# MCXN947_cm33_core0 register map
Vendor: nxp.com; File version: 1.0
CPU: CM33 r2p0, little endian, MPU, FPU, VTOR, 3 interrupt priority bits
Registers are 32-bit, read-write, reset 0x0 unless marked. A register's access mark holds for its fields unless they carry their own. Offsets are from the block's base; [hi:lo] are bit positions; {n}, {i} and the like mark numbered series; 'fields as' and 'values as' point back to an identical list.

## PORT0 — PORT
Base 0x40116000
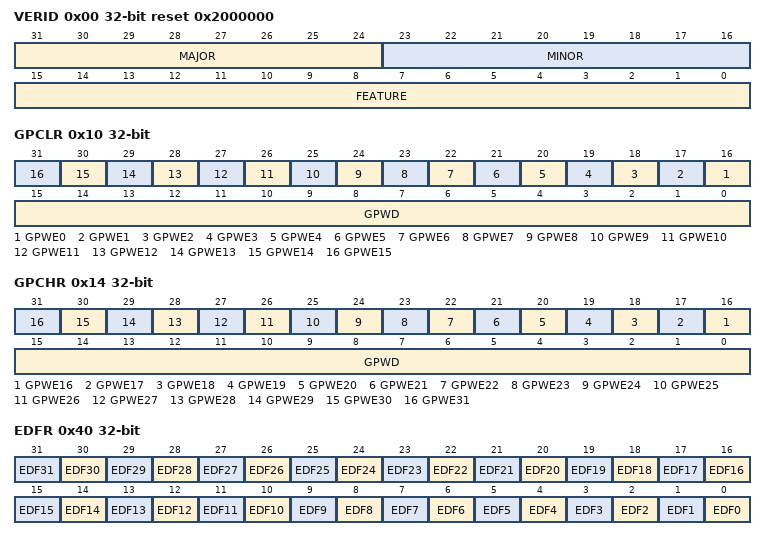
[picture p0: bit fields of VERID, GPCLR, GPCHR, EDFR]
0x00 VERID ro reset 0x2000000 — Version ID
  [31:24] MAJOR — Major Version Number
  [23:16] MINOR — Minor Version Number
  [15:0] FEATURE — Feature Specification Number
    0=Basic implementation
0x10 GPCLR — Global Pin Control Low
  [n+16] GPWE{n} (n=0..15) — Global Pin Write Enable
    0=gpwe0 (Not updated); 1=gpwe1 (Updated)
  [15:0] GPWD — Global Pin Write Data
0x14 GPCHR — Global Pin Control High
  [n] GPWE{n} (n=16..31) — Global Pin Write Enable
    0=gpwe0 (Not updated); 1=gpwe1 (Updated)
  [15:0] GPWD — Global Pin Write Data
0x20 CONFIG — Configuration
  [0] RANGE — Port Voltage Range
    0=1.71 V-3.6 V; 1=2.70 V-3.6 V
0x40 EDFR ro reset not defined — EFT Detect Flag
  [all] fields
    0=edie0 (No EFT event detected); 1=edie1 (High or/and low EFT event detected)
  [n] EDF{n} (n=0..31) — EFT Detect Flag
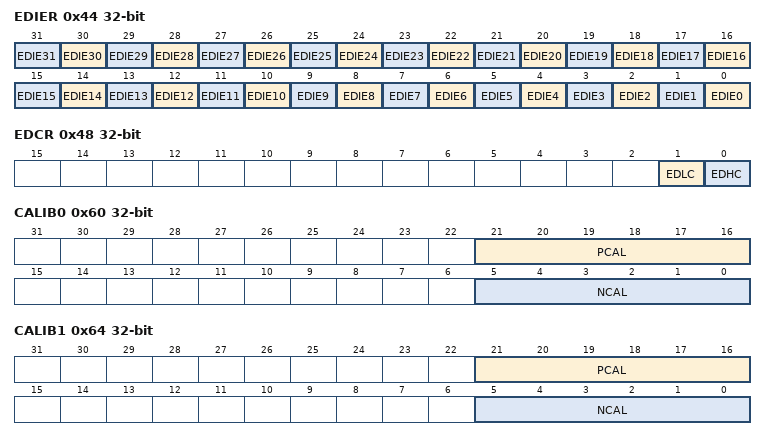
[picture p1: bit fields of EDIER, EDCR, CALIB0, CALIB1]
0x44 EDIER — EFT Detect Interrupt Enable
  [all] fields
    0=edie0 (Interrupt not generated upon detection of the EFT event); 1=edie1 (Interrupt generated upon detection of the EFT event)
  [n] EDIE{n} (n=0..31) — EFT Detect Interrupt Enable
0x48 EDCR — EFT Detect Clear
  [1] EDLC — EFT Detect Low Clear
    0=Does not clear; 1=Clears
  [0] EDHC — EFT Detect High Clear
    0=Does not clear; 1=Clears
0x60 CALIB0 (reset mask 0xFFC0FFC0) — Calibration 0
  [21:16] PCAL — Calibration of PMOS Output Driver
  [5:0] NCAL — Calibration of NMOS Output Driver
0x64 CALIB1 (reset mask 0xFFC0FFC0) — Calibration 1
  fields as CALIB0
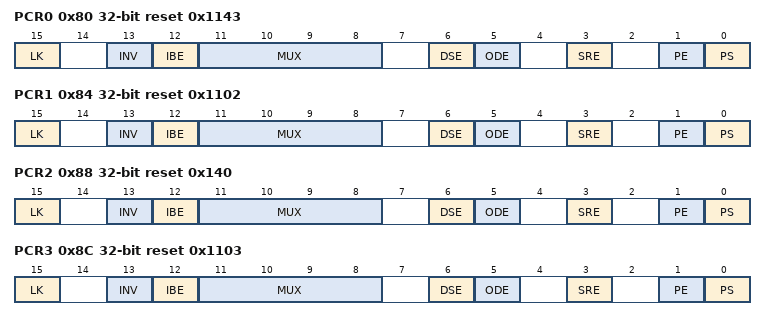
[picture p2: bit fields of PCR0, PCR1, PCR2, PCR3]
0x80 PCR0 reset 0x1143 — Pin Control 0
  [15] LK — Lock Register
    0=Does not lock; 1=Locks
  [13] INV — Invert Input
    0=Does not invert; 1=Inverts
  [12] IBE — Input Buffer Enable
    0=Disables; 1=Enables
  [11:8] MUX — Pin Multiplex Control
    0=Alternative 0 (GPIO); {v}=Alternative {v} (chip-specific) (v=1..13)
  [6] DSE — Drive Strength Enable
    0=Low; 1=High
  [5] ODE — Open Drain Enable
    0=Disables; 1=Enables
  [3] SRE — Slew Rate Enable
    0=Fast; 1=Slow
  [1] PE — Pull Enable
    0=Disables; 1=Enables
  [0] PS — Pull Select
    0=Enables internal pulldown resistor; 1=Enables internal pullup resistor
0x84 PCR1 reset 0x1102 — Pin Control 1
  fields as PCR0
0x88 PCR2 reset 0x140 — Pin Control 2
  fields as PCR0
0x8C PCR3 reset 0x1103 — Pin Control 3
  fields as PCR0
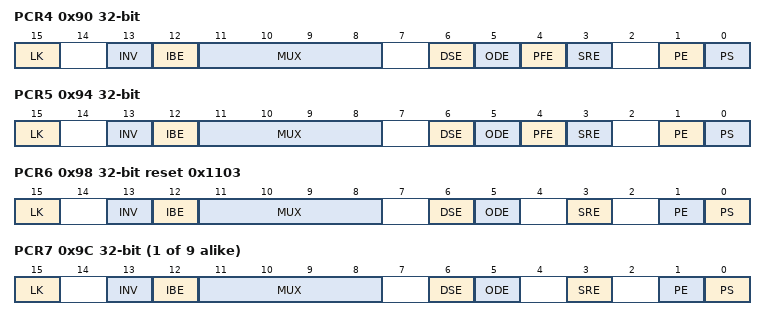
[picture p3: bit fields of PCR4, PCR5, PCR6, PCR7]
0x90 PCR4 — Pin Control 4
  [15] LK — Lock Register
    0=Does not lock; 1=Locks
  [13] INV — Invert Input
    0=Does not invert; 1=Inverts
  [12] IBE — Input Buffer Enable
    0=Disables; 1=Enables
  [11:8] MUX — Pin Multiplex Control
    values as PCR0.MUX
  [6] DSE — Drive Strength Enable
    0=Low; 1=High
  [5] ODE — Open Drain Enable
    0=Disables; 1=Enables
  [4] PFE — Passive Filter Enable
    0=Disables; 1=Enables
  [3] SRE — Slew Rate Enable
    0=Fast; 1=Slow
  [1] PE — Pull Enable
    0=Disables; 1=Enables
  [0] PS — Pull Select
    values as PCR0.PS
0x94 PCR5 — Pin Control 5
  fields as PCR4
0x98 PCR6 reset 0x1103 — Pin Control 6
  fields as PCR0
{0x80+4i} PCR{i} (i=7..15) — Pin Control {i}
  fields as PCR0
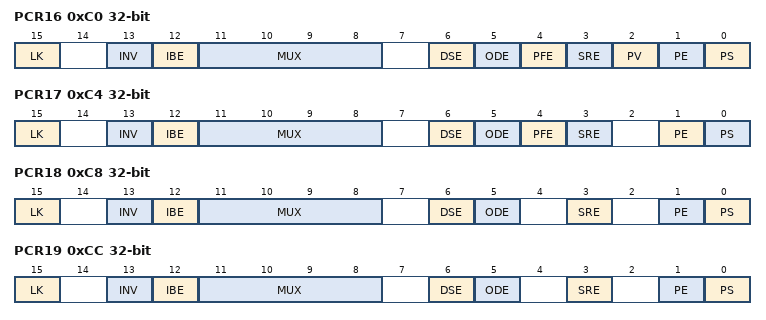
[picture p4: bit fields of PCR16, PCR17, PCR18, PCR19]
0xC0 PCR16 — Pin Control 16
  [15] LK — Lock Register
    0=Does not lock; 1=Locks
  [13] INV — Invert Input
    0=Does not invert; 1=Inverts
  [12] IBE — Input Buffer Enable
    0=Disables; 1=Enables
  [11:8] MUX — Pin Multiplex Control
    values as PCR0.MUX
  [6] DSE — Drive Strength Enable
    0=Low; 1=High
  [5] ODE — Open Drain Enable
    0=Disables; 1=Enables
  [4] PFE — Passive Filter Enable
    0=Disables; 1=Enables
  [3] SRE — Slew Rate Enable
    0=Fast; 1=Slow
  [2] PV — Pull Value
    0=Low; 1=High
  [1] PE — Pull Enable
    0=Disables; 1=Enables
  [0] PS — Pull Select
    values as PCR0.PS
0xC4 PCR17 — Pin Control 17
  fields as PCR4
0xC8 PCR18 — Pin Control 18
  fields as PCR0
0xCC PCR19 — Pin Control 19
  fields as PCR0
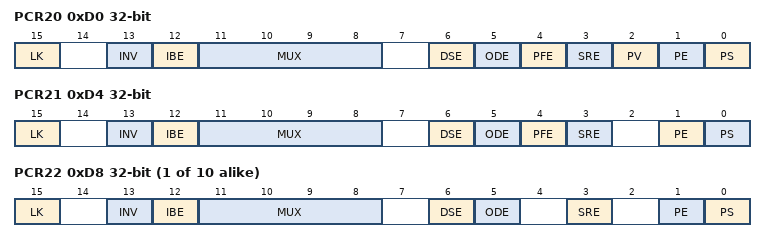
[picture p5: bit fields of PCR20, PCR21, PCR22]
0xD0 PCR20 — Pin Control 20
  fields as PCR16
0xD4 PCR21 — Pin Control 21
  fields as PCR4
{0x80+4i} PCR{i} (i=22..31) — Pin Control {i}
  fields as PCR0

## PORT1 — PORT
Base 0x40117000
Registers as PORT0, without PCR{n} (n=24..29); these are added or differ:
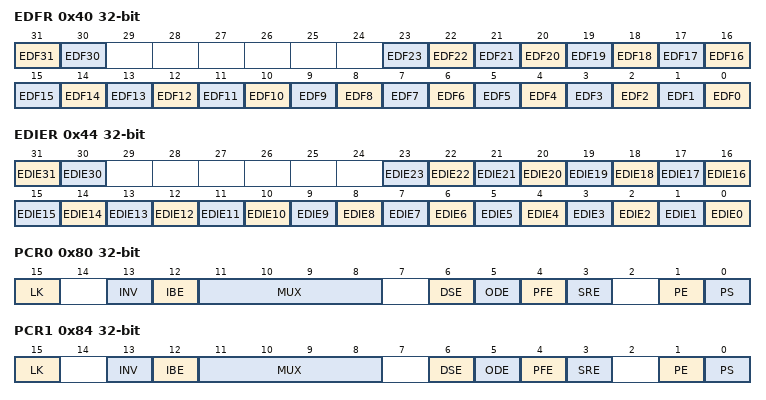
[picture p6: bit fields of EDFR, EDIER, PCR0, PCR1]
0x40 EDFR ro reset not defined — EFT Detect Flag
  [all] fields
    0=edie0 (No EFT event detected); 1=edie1 (High or/and low EFT event detected)
  [31] EDF31 — EFT Detect Flag
  [30] EDF30 — EFT Detect Flag
  [n] EDF{n} (n=0..23) — EFT Detect Flag
0x44 EDIER — EFT Detect Interrupt Enable
  [all] fields
    0=edie0 (Interrupt not generated upon detection of the EFT event); 1=edie1 (Interrupt generated upon detection of the EFT event)
  [31] EDIE31 — EFT Detect Interrupt Enable
  [30] EDIE30 — EFT Detect Interrupt Enable
  [n] EDIE{n} (n=0..23) — EFT Detect Interrupt Enable
0x80 PCR0 — Pin Control 0
  fields as PORT0.PCR4
0x84 PCR1 — Pin Control 1
  fields as PORT0.PCR4
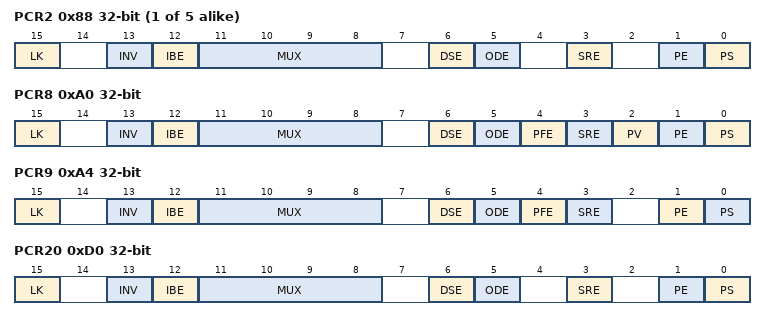
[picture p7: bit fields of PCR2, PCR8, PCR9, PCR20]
{0x80+4i} PCR{i} (i=2..6) — Pin Control {i}
  fields as PORT0.PCR0
0xA0 PCR8 — Pin Control 8
  fields as PORT0.PCR16
0xA4 PCR9 — Pin Control 9
  fields as PORT0.PCR4
0xD0 PCR20 — Pin Control 20
  fields as PORT0.PCR0
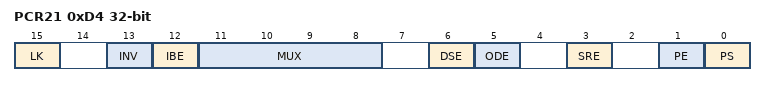
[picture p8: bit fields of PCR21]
0xD4 PCR21 — Pin Control 21
  fields as PORT0.PCR0

## PORT2 — PORT
Base 0x40118000
Registers as PORT1, without PCR{n} (n=12..23), PCR30, PCR31; these are added or differ:
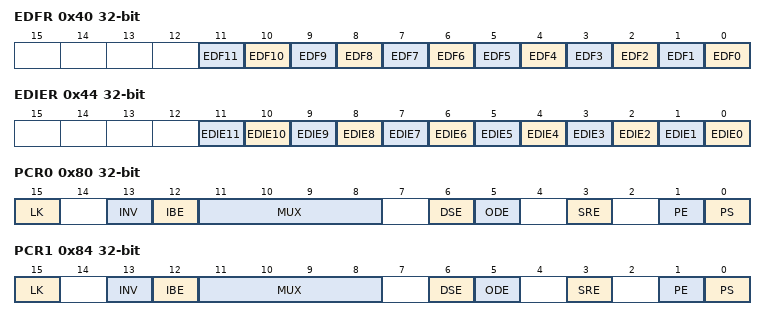
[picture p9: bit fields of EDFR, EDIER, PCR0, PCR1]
0x40 EDFR ro reset not defined — EFT Detect Flag
  [all] fields
    0=edie0 (No EFT event detected); 1=edie1 (High or/and low EFT event detected)
  [n] EDF{n} (n=0..11) — EFT Detect Flag
0x44 EDIER — EFT Detect Interrupt Enable
  [all] fields
    0=edie0 (Interrupt not generated upon detection of the EFT event); 1=edie1 (Interrupt generated upon detection of the EFT event)
  [n] EDIE{n} (n=0..11) — EFT Detect Interrupt Enable
0x80 PCR0 — Pin Control 0
  fields as PORT0.PCR0
0x84 PCR1 — Pin Control 1
  fields as PORT0.PCR0
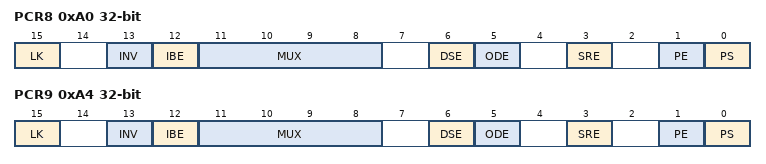
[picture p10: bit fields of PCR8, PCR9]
0xA0 PCR8 — Pin Control 8
  fields as PORT0.PCR0
0xA4 PCR9 — Pin Control 9
  fields as PORT0.PCR0

## PORT3 — PORT
Base 0x40119000
Registers as PORT1, without PCR30, PCR31; these are added or differ:
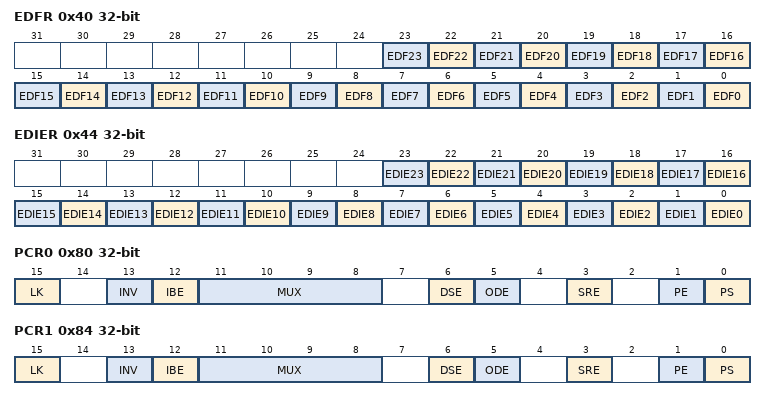
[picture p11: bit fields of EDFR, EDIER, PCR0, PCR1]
0x40 EDFR ro reset not defined — EFT Detect Flag
  [all] fields
    0=edie0 (No EFT event detected); 1=edie1 (High or/and low EFT event detected)
  [n] EDF{n} (n=0..23) — EFT Detect Flag
0x44 EDIER — EFT Detect Interrupt Enable
  [all] fields
    0=edie0 (Interrupt not generated upon detection of the EFT event); 1=edie1 (Interrupt generated upon detection of the EFT event)
  [n] EDIE{n} (n=0..23) — EFT Detect Interrupt Enable
0x80 PCR0 — Pin Control 0
  fields as PORT0.PCR0
0x84 PCR1 — Pin Control 1
  fields as PORT0.PCR0
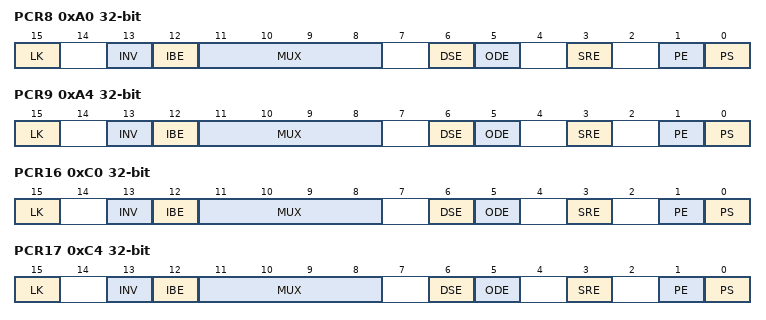
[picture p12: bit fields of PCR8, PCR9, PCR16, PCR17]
0xA0 PCR8 — Pin Control 8
  fields as PORT0.PCR0
0xA4 PCR9 — Pin Control 9
  fields as PORT0.PCR0
0xC0 PCR16 — Pin Control 16
  fields as PORT0.PCR0
0xC4 PCR17 — Pin Control 17
  fields as PORT0.PCR0

## PORT4 — PORT
Base 0x4011A000
Registers as PORT3, without CALIB0, CALIB1, PCR{n} (n=8..11); these are added or differ:
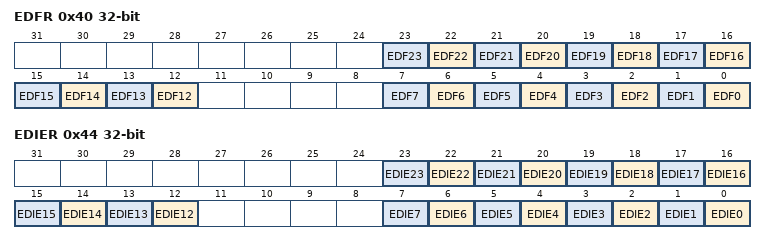
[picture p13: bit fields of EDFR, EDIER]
0x40 EDFR ro reset not defined — EFT Detect Flag
  [all] fields
    0=edie0 (No EFT event detected); 1=edie1 (High or/and low EFT event detected)
  [n] EDF{n} (n=12..23) — EFT Detect Flag
  [n] EDF{n} (n=0..7) — EFT Detect Flag
0x44 EDIER — EFT Detect Interrupt Enable
  [all] fields
    0=edie0 (Interrupt not generated upon detection of the EFT event); 1=edie1 (Interrupt generated upon detection of the EFT event)
  [n] EDIE{n} (n=12..23) — EFT Detect Interrupt Enable
  [n] EDIE{n} (n=0..7) — EFT Detect Interrupt Enable
